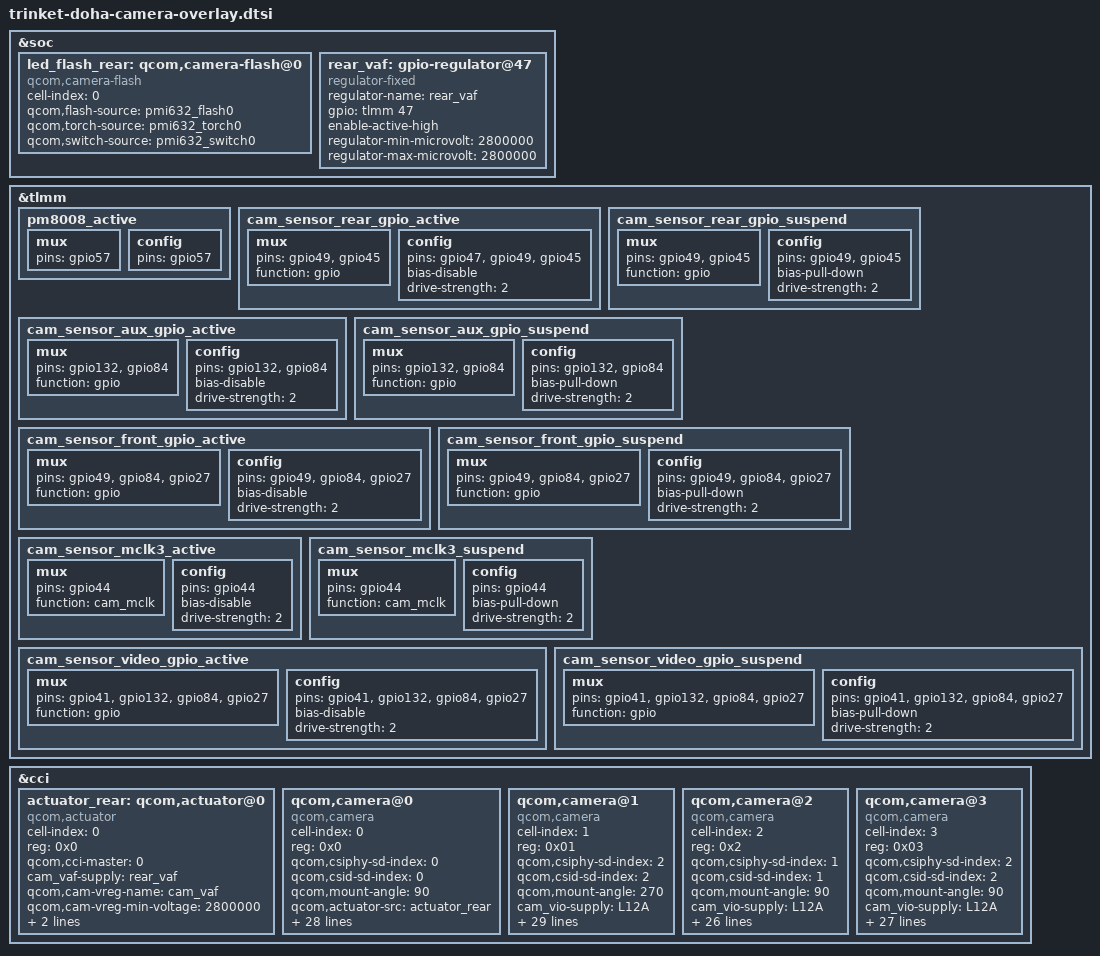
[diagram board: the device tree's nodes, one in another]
/*
 * Copyright (c) 2019, The Linux Foundation. All rights reserved.
 *
 * This program is free software; you can redistribute it and/or modify
 * it under the terms of the GNU General Public License version 2 and
 * only version 2 as published by the Free Software Foundation.
 *
 * This program is distributed in the hope that it will be useful,
 * but WITHOUT ANY WARRANTY; without even the implied warranty of
 * MERCHANTABILITY or FITNESS FOR A PARTICULAR PURPOSE.  See the
 * GNU General Public License for more details.
 */
&soc {
	led_flash_rear: qcom,camera-flash@0 {
		cell-index = <0>;
		compatible = "qcom,camera-flash";
		qcom,flash-source = <&pmi632_flash0>;
		qcom,torch-source = <&pmi632_torch0>;
		qcom,switch-source = <&pmi632_switch0>;
		status = "ok";
	};

	rear_vaf: gpio-regulator@47 {
		compatible = "regulator-fixed";
		regulator-name = "rear_vaf";
		gpio = <&tlmm 47 0>;
		enable-active-high;
		regulator-min-microvolt = <2800000>;
		regulator-max-microvolt = <2800000>;
	};
};

&tlmm {
	pm8008_active: pm8008_active {
		mux {
			pins = "gpio57";
		};

		config {
			pins = "gpio57";
		};
	};

	cam_sensor_rear_gpio_active: cam_sensor_rear_gpio_active {
		/* AF, AVDD, DVDD */
		mux {
			pins = "gpio49", "gpio45";
			function = "gpio";
		};

		config {
			pins = "gpio47", "gpio49", "gpio45";
			bias-disable; /* No PULL */
			drive-strength = <2>; /* 2 MA */
		};
	};

	cam_sensor_rear_gpio_suspend: cam_sensor_rear_gpio_suspend {
		/* AF, AVDD, DVDD */
		mux {
			pins = "gpio49", "gpio45";
			function = "gpio";
		};

		config {
			pins = "gpio49", "gpio45";
			bias-pull-down; /* PULL DOWN */
			drive-strength = <2>; /* 2 MA */
		};
	};

	cam_sensor_aux_gpio_active: cam_sensor_aux_gpio_active {
		/* AVDD, DVDD */
		mux {
			pins = "gpio132", "gpio84";
			function = "gpio";
		};

		config {
			pins = "gpio132", "gpio84";
			bias-disable; /* No PULL */
			drive-strength = <2>; /* 2 MA */
		};
	};

	cam_sensor_aux_gpio_suspend: cam_sensor_aux_gpio_suspend {
		/* AVDD, DVDD */
		mux {
			pins = "gpio132", "gpio84";
			function = "gpio";
		};

		config {
			pins = "gpio132", "gpio84";
			bias-pull-down; /* PULL DOWN */
			drive-strength = <2>; /* 2 MA */
		};
	};

	cam_sensor_front_gpio_active: cam_sensor_front_gpio_active {
		/* AVDD, DVDD, MIPI_SEL */
		mux {
			pins = "gpio49", "gpio84", "gpio27";
			function = "gpio";
		};

		config {
			pins = "gpio49", "gpio84", "gpio27";
			bias-disable; /* No PULL */
			drive-strength = <2>; /* 2 MA */
		};
	};

	cam_sensor_front_gpio_suspend: cam_sensor_front_gpio_suspend {
		/* AVDD, DVDD, MIPI_SEL */
		mux {
			pins = "gpio49", "gpio84", "gpio27";
			function = "gpio";
		};

		config {
			pins = "gpio49", "gpio84", "gpio27";
			bias-pull-down; /* PULL DOWN */
			drive-strength = <2>; /* 2 MA */
		};
	};

	cam_sensor_mclk3_active: cam_sensor_mclk3_active {
		/* MCLK3 */
		mux {
			pins = "gpio44";
			function = "cam_mclk";
		};

		config {
			pins = "gpio44";
			bias-disable; /* No PULL */
			drive-strength = <2>; /* 2 MA */
		};
	};

	cam_sensor_mclk3_suspend: cam_sensor_mclk3_suspend {
		/* MCLK3 */
		mux {
			pins = "gpio44";
			function = "cam_mclk";
		};

		config {
			pins = "gpio44";
			bias-pull-down; /* PULL DOWN */
			drive-strength = <2>; /* 2 MA */
		};
	};
	cam_sensor_video_gpio_active: cam_sensor_video_gpio_active {
		/* RESET, AVDD, DVDD, MIPI_SEL */
		mux {
			pins = "gpio41", "gpio132", "gpio84", "gpio27";
			function = "gpio";
		};

		config {
			pins = "gpio41", "gpio132", "gpio84", "gpio27";
			bias-disable; /* No PULL */
			drive-strength = <2>; /* 2 MA */
		};
	};

	cam_sensor_video_gpio_suspend: cam_sensor_video_gpio_suspend {
		/* RESET, AVDD, DVDD, MIPI_SEL */
		mux {
			pins = "gpio41", "gpio132", "gpio84", "gpio27";
			function = "gpio";
		};

		config {
			pins = "gpio41", "gpio132", "gpio84", "gpio27";
			bias-pull-down; /* PULL DOWN */
			drive-strength = <2>; /* 2 MA */
		};
	};
};

&cci {
	actuator_rear: qcom,actuator@0 {
		cell-index = <0>;
		reg = <0x0>;
		compatible = "qcom,actuator";
		qcom,cci-master = <0>;
		cam_vaf-supply = <&rear_vaf>;
		qcom,cam-vreg-name = "cam_vaf";
		qcom,cam-vreg-min-voltage = <2800000>;
		qcom,cam-vreg-max-voltage = <2800000>;
		qcom,cam-vreg-op-mode = <80000>;
	};

	qcom,camera@0 {
		cell-index = <0>;
		compatible = "qcom,camera";
		reg = <0x0>;
		qcom,csiphy-sd-index = <0>;
		qcom,csid-sd-index = <0>;
		qcom,mount-angle = <90>;
		qcom,actuator-src = <&actuator_rear>;
		qcom,led-flash-src = <&led_flash_rear>;
		cam_vio-supply = <&L12A>;
		cam_vaf_supply = <&rear_vaf>;
		qcom,cam-vreg-name = "cam_vio", "cam_vaf";
		qcom,cam-vreg-min-voltage = <1800000 2800000>;
		qcom,cam-vreg-max-voltage = <1800000 2800000>;
		qcom,cam-vreg-op-mode = <80000 100000>;
		qcom,gpio-no-mux = <0>;
		pinctrl-names = "cam_default", "cam_suspend";
		pinctrl-0 = <&cam_sensor_mclk0_active
					&cam_sensor_rear_active
					&cam_sensor_rear_gpio_active>;
		pinctrl-1 = <&cam_sensor_mclk0_suspend
					&cam_sensor_rear_suspend
					&cam_sensor_rear_gpio_suspend>;
		gpios = <&tlmm 34 0>,
				<&tlmm 48 0>,
				<&tlmm 49 0>,
				<&tlmm 45 0>;
		qcom,gpio-reset = <1>;
		qcom,gpio-vana = <2>;
		qcom,gpio-vdig = <3>;
		qcom,gpio-req-tbl-num = <0 1 2 3>;
		qcom,gpio-req-tbl-flags = <1 0 0 0>;
		qcom,gpio-req-tbl-label = "CAM_R_MCLK",
								  "CAM_R_RESET",
								  "CAM_R_AVDD",
								  "CAM_R_DVDD";
		qcom,sensor-position = <0>;
		qcom,sensor-mode = <0>;
		qcom,cci-master = <0>;
		status = "ok";
		clocks = <&clock_gcc GCC_CAMSS_MCLK0_CLK_SRC>,
					<&clock_gcc GCC_CAMSS_MCLK0_CLK>;
		clock-names = "cam_src_clk", "cam_clk";
		qcom,clock-rates = <24000000 0>;
	};

	qcom,camera@1 {
		cell-index = <1>;
		compatible = "qcom,camera";
		reg = <0x01>;
		qcom,csiphy-sd-index = <2>;
		qcom,csid-sd-index = <2>;
		qcom,mount-angle = <270>;
		cam_vio-supply = <&L12A>;
		cam_clk-supply = <&camss_top_gdsc>;
		qcom,cam-vreg-name = "cam_vio";
		qcom,cam-vreg-min-voltage = <1800000>;
		qcom,cam-vreg-max-voltage = <1800000>;
		qcom,cam-vreg-op-mode = <80000>;
		qcom,gpio-no-mux = <0>;
		pinctrl-names = "cam_default", "cam_suspend";
		pinctrl-0 = <&cam_sensor_mclk1_active
					&cam_sensor_front_active
					&cam_sensor_front_gpio_active>;
		pinctrl-1 = <&cam_sensor_mclk1_suspend
					&cam_sensor_front_suspend
					&cam_sensor_front_gpio_suspend>;
		gpios = <&tlmm 35 0>,
				<&tlmm 42 0>,
				<&tlmm 49 0>,
				<&tlmm 84 0>,
				<&tlmm 27 0>;
		qcom,gpio-reset = <1>;
		qcom,gpio-vana = <2>;
		qcom,gpio-vdig = <3>;
		qcom,gpio-custom1 = <4>;
		qcom,gpio-req-tbl-num = <0 1 2 3 4>;
		qcom,gpio-req-tbl-flags = <1 0 0 0 0>;
		qcom,gpio-req-tbl-label = "CAM_F_MCLK",
								  "CAM_F_RESET",
								  "CAM_F_AVDD",
								  "CAM_F_DVDD",
								  "CAM_MIPI_SEL";
		qcom,sensor-position = <1>;
		qcom,sensor-mode = <1>;
		qcom,cci-master = <1>;
		status = "ok";
		clocks = <&clock_gcc GCC_CAMSS_MCLK1_CLK_SRC>,
				<&clock_gcc GCC_CAMSS_MCLK1_CLK>;
		clock-names = "cam_src_clk", "cam_clk";
		qcom,clock-rates = <24000000 0>;
	};

	qcom,camera@2 {
		cell-index = <2>;
		compatible = "qcom,camera";
		reg = <0x2>;
		qcom,csiphy-sd-index = <1>;
		qcom,csid-sd-index = <1>;
		qcom,mount-angle = <90>;
		cam_vio-supply = <&L12A>;
		cam_clk-supply = <&camss_top_gdsc>;
		qcom,cam-vreg-name = "cam_vio";
		qcom,cam-vreg-min-voltage = <1800000>;
		qcom,cam-vreg-max-voltage = <1800000>;
		qcom,cam-vreg-op-mode = <80000>;
		qcom,gpio-no-mux = <0>;
		pinctrl-names = "cam_default", "cam_suspend";
		pinctrl-0 = <&cam_sensor_mclk2_active
					&cam_sensor_rear2_active
					&cam_sensor_aux_gpio_active>;
		pinctrl-1 = <&cam_sensor_mclk2_suspend
					&cam_sensor_rear2_suspend
					&cam_sensor_aux_gpio_suspend>;
		gpios = <&tlmm 36 0>,
				<&tlmm 46 0>,
				<&tlmm 132 0>,
				<&tlmm 84 0>;
		qcom,gpio-reset = <1>;
		qcom,gpio-vana = <2>;
		qcom,gpio-vdig = <3>;
		qcom,gpio-req-tbl-num = <0 1 2 3>;
		qcom,gpio-req-tbl-flags = <1 0 0 0>;
		qcom,gpio-req-tbl-label = "CAM_S_MCLK",
								  "CAM_S_RESET",
								  "CAM_S_AVDD",
								  "CAM_S_DVDD";
		qcom,sensor-position = <0>;
		qcom,sensor-mode = <0>;
		qcom,cci-master = <1>;
		status = "ok";
		clocks = <&clock_gcc GCC_CAMSS_MCLK2_CLK_SRC>,
			<&clock_gcc GCC_CAMSS_MCLK2_CLK>;
		clock-names = "cam_src_clk", "cam_clk";
		qcom,clock-rates = <24000000 0>;
	};

	qcom,camera@3 {
		cell-index = <3>;
		compatible = "qcom,camera";
		reg = <0x03>;
		qcom,csiphy-sd-index = <2>;
		qcom,csid-sd-index = <2>;
		qcom,mount-angle = <90>;
		cam_vio-supply = <&L12A>;
		cam_clk-supply = <&camss_top_gdsc>;
		qcom,cam-vreg-name = "cam_vio";
		qcom,cam-vreg-min-voltage = <1800000>;
		qcom,cam-vreg-max-voltage = <1800000>;
		qcom,cam-vreg-op-mode = <80000>;
		qcom,gpio-no-mux = <0>;
		pinctrl-names = "cam_default", "cam_suspend";
		pinctrl-0 = <&cam_sensor_mclk3_active
					&cam_sensor_video_gpio_active>;
		pinctrl-1 = <&cam_sensor_mclk3_suspend
					&cam_sensor_video_gpio_suspend>;
		gpios = <&tlmm 44 0>,
				<&tlmm 41 0>,
				<&tlmm 132 0>,
				<&tlmm 84 0>,
				<&tlmm 27 0>;
		qcom,gpio-reset = <1>;
		qcom,gpio-vana = <2>;
		qcom,gpio-vdig = <3>;
		qcom,gpio-custom1 = <4>;
		qcom,gpio-req-tbl-num = <0 1 2 3 4>;
		qcom,gpio-req-tbl-flags = <1 0 0 0 0>;
		qcom,gpio-req-tbl-label = "CAM_V_MCLK",
								  "CAM_V_RESET",
								  "CAM_V_AVDD",
								  "CAM_V_DVDD",
								  "CAM_MIPI_SEL";
		qcom,sensor-position = <0>;
		qcom,sensor-mode = <0>;
		qcom,cci-master = <0>;
		status = "ok";
		clocks = <&clock_gcc GCC_CAMSS_MCLK3_CLK_SRC>,
				<&clock_gcc GCC_CAMSS_MCLK3_CLK>;
		clock-names = "cam_src_clk", "cam_clk";
		qcom,clock-rates = <24000000 0>;
	};
};

